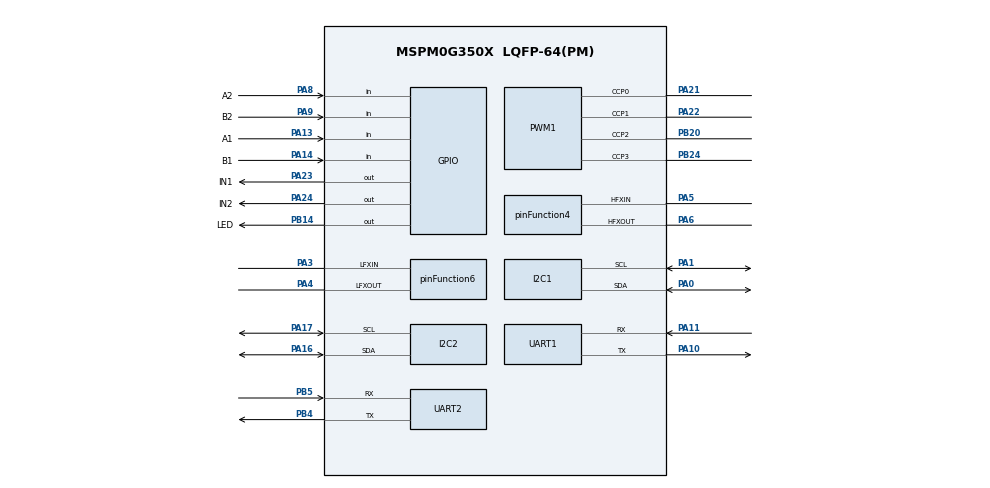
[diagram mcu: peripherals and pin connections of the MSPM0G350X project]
/**
 * @cliArgs --device "MSPM0G350X" --part "Default" --package "LQFP-64(PM)" --product "mspm0_sdk@2.05.01.01"
 * @versions {"tool":"1.24.0+4110"}
 */

/**
 * Import the modules used in this configuration.
 */
const GPIO   = scripting.addModule("/ti/driverlib/GPIO", {}, false);
const GPIO1  = GPIO.addInstance();
const GPIO2  = GPIO.addInstance();
const GPIO3  = GPIO.addInstance();
const I2C    = scripting.addModule("/ti/driverlib/I2C", {}, false);
const I2C1   = I2C.addInstance();
const I2C2   = I2C.addInstance();
const PWM    = scripting.addModule("/ti/driverlib/PWM", {}, false);
const PWM1   = PWM.addInstance();
const SYSCTL = scripting.addModule("/ti/driverlib/SYSCTL");
const TIMER  = scripting.addModule("/ti/driverlib/TIMER", {}, false);
const TIMER1 = TIMER.addInstance();
const UART   = scripting.addModule("/ti/driverlib/UART", {}, false);
const UART1  = UART.addInstance();
const UART2  = UART.addInstance();

/**
 * Write custom configuration values to the imported modules.
 */
const divider2       = system.clockTree["HFCLK4MFPCLKDIV"];
divider2.divideValue = 10;

const divider4       = system.clockTree["PLL_CLK0_DIV"];
divider4.divideValue = 4;

const divider9       = system.clockTree["UDIV"];
divider9.divideValue = 2;

const gate7  = system.clockTree["MFCLKGATE"];
gate7.enable = true;

const gate8  = system.clockTree["MFPCLKGATE"];
gate8.enable = true;

const multiplier2         = system.clockTree["PLL_QDIV"];
multiplier2.multiplyValue = 10;

const mux2       = system.clockTree["CANCLKMUX"];
mux2.inputSelect = "CANCLKMUX_PLLCLK1_OUT";

const mux4       = system.clockTree["EXHFMUX"];
mux4.inputSelect = "EXHFMUX_XTAL";

const mux5       = system.clockTree["EXLFMUX"];
mux5.inputSelect = "EXLFMUX_XTAL";

const mux8       = system.clockTree["HSCLKMUX"];
mux8.inputSelect = "HSCLKMUX_SYSPLL0";

const pinFunction4                        = system.clockTree["HFXT"];
pinFunction4.inputFreq                    = 40;
pinFunction4.enable                       = true;
pinFunction4.peripheral.$assign           = "SYSCTL";
pinFunction4.peripheral.hfxInPin.$assign  = "PA5";
pinFunction4.peripheral.hfxOutPin.$assign = "PA6";

const pinFunction6                        = system.clockTree["LFXT"];
pinFunction6.inputFreq                    = 32.768;
pinFunction6.enable                       = true;
pinFunction6.peripheral.$assign           = "SYSCTL";
pinFunction6.peripheral.lfxInPin.$assign  = "PA3";
pinFunction6.peripheral.lfxOutPin.$assign = "PA4";

GPIO1.$name                         = "DEBUG";
GPIO1.associatedPins[0].$name       = "LED";
GPIO1.associatedPins[0].assignedPin = "14";
GPIO1.associatedPins[0].pin.$assign = "PB14";

const Board = scripting.addModule("/ti/driverlib/Board", {}, false);

GPIO2.$name                         = "ENCODER";
GPIO2.associatedPins.create(4);
GPIO2.associatedPins[0].direction   = "INPUT";
GPIO2.associatedPins[0].interruptEn = true;
GPIO2.associatedPins[0].polarity    = "RISE";
GPIO2.associatedPins[0].$name       = "A1";
GPIO2.associatedPins[0].pin.$assign = "PA13";
GPIO2.associatedPins[1].direction   = "INPUT";
GPIO2.associatedPins[1].interruptEn = true;
GPIO2.associatedPins[1].polarity    = "RISE";
GPIO2.associatedPins[1].$name       = "B1";
GPIO2.associatedPins[1].pin.$assign = "PA14";
GPIO2.associatedPins[2].$name       = "A2";
GPIO2.associatedPins[2].direction   = "INPUT";
GPIO2.associatedPins[2].interruptEn = true;
GPIO2.associatedPins[2].polarity    = "RISE";
GPIO2.associatedPins[2].pin.$assign = "PA8";
GPIO2.associatedPins[3].$name       = "B2";
GPIO2.associatedPins[3].direction   = "INPUT";
GPIO2.associatedPins[3].interruptEn = true;
GPIO2.associatedPins[3].polarity    = "RISE";
GPIO2.associatedPins[3].pin.$assign = "PA9";

GPIO3.$name                         = "MOTOR_DIR";
GPIO3.port                          = "PORTA";
GPIO3.associatedPins.create(2);
GPIO3.associatedPins[0].$name       = "IN1";
GPIO3.associatedPins[0].pin.$assign = "PA23";
GPIO3.associatedPins[1].$name       = "IN2";
GPIO3.associatedPins[1].pin.$assign = "PA24";

I2C1.$name                           = "I2C_0";
I2C1.basicEnableController           = true;
I2C1.basicControllerStandardBusSpeed = "Fast";
I2C1.peripheral.$assign              = "I2C0";
I2C1.peripheral.sdaPin.$assign       = "PA0";
I2C1.peripheral.sclPin.$assign       = "PA1";
I2C1.sdaPinConfig.$name              = "ti_driverlib_gpio_GPIOPinGeneric0";
I2C1.sclPinConfig.$name              = "ti_driverlib_gpio_GPIOPinGeneric1";

I2C2.$name                           = "I2C_1";
I2C2.basicEnableController           = true;
I2C2.basicControllerStandardBusSpeed = "Fast";
I2C2.peripheral.$assign              = "I2C1";
I2C2.peripheral.sdaPin.$assign       = "PA16";
I2C2.peripheral.sclPin.$assign       = "PA17";
I2C2.sdaPinConfig.$name              = "ti_driverlib_gpio_GPIOPinGeneric4";
I2C2.sclPinConfig.$name              = "ti_driverlib_gpio_GPIOPinGeneric5";

PWM1.clockDivider                       = 8;
PWM1.ccIndex                            = [0,1,2,3];
PWM1.pwmMode                            = "EDGE_ALIGN_UP";
PWM1.$name                              = "MOTOR_PWM";
PWM1.PWM_CHANNEL_0.$name                = "ti_driverlib_pwm_PWMTimerCC0";
PWM1.PWM_CHANNEL_1.$name                = "ti_driverlib_pwm_PWMTimerCC1";
PWM1.ccp0PinConfig.direction            = scripting.forceWrite("OUTPUT");
PWM1.ccp0PinConfig.hideOutputInversion  = scripting.forceWrite(false);
PWM1.ccp0PinConfig.onlyInternalResistor = scripting.forceWrite(false);
PWM1.ccp0PinConfig.passedPeripheralType = scripting.forceWrite("Digital");
PWM1.ccp0PinConfig.$name                = "ti_driverlib_gpio_GPIOPinGeneric6";
PWM1.ccp1PinConfig.direction            = scripting.forceWrite("OUTPUT");
PWM1.ccp1PinConfig.hideOutputInversion  = scripting.forceWrite(false);
PWM1.ccp1PinConfig.onlyInternalResistor = scripting.forceWrite(false);
PWM1.ccp1PinConfig.passedPeripheralType = scripting.forceWrite("Digital");
PWM1.ccp1PinConfig.$name                = "ti_driverlib_gpio_GPIOPinGeneric7";
PWM1.peripheral.$assign                 = "TIMA0";
PWM1.peripheral.ccp0Pin.$assign         = "PA21";
PWM1.peripheral.ccp1Pin.$assign         = "PA22";
PWM1.peripheral.ccp2Pin.$assign         = "PB20";
PWM1.peripheral.ccp3Pin.$assign         = "PB24";
PWM1.PWM_CHANNEL_2.$name                = "ti_driverlib_pwm_PWMTimerCC2";
PWM1.PWM_CHANNEL_3.$name                = "ti_driverlib_pwm_PWMTimerCC3";
PWM1.ccp2PinConfig.direction            = scripting.forceWrite("OUTPUT");
PWM1.ccp2PinConfig.hideOutputInversion  = scripting.forceWrite(false);
PWM1.ccp2PinConfig.onlyInternalResistor = scripting.forceWrite(false);
PWM1.ccp2PinConfig.passedPeripheralType = scripting.forceWrite("Digital");
PWM1.ccp2PinConfig.$name                = "ti_driverlib_gpio_GPIOPinGeneric8";
PWM1.ccp3PinConfig.direction            = scripting.forceWrite("OUTPUT");
PWM1.ccp3PinConfig.hideOutputInversion  = scripting.forceWrite(false);
PWM1.ccp3PinConfig.onlyInternalResistor = scripting.forceWrite(false);
PWM1.ccp3PinConfig.passedPeripheralType = scripting.forceWrite("Digital");
PWM1.ccp3PinConfig.$name                = "ti_driverlib_gpio_GPIOPinGeneric9";

SYSCTL.forceDefaultClkConfig = true;
SYSCTL.clockTreeEn           = true;
scripting.suppress("For best practices when the CPUCLK is running at 32MHz and above, clear the flash status bit using DL_FlashCTL_executeClearStatus\\(\\) before executing any flash operation\\. Otherwise there may be false positives\\.", SYSCTL);

TIMER1.timerClkDiv        = 8;
TIMER1.$name              = "TIMER_ENC";
TIMER1.timerClkPrescale   = 10;
TIMER1.timerMode          = "PERIODIC";
TIMER1.timerPeriod        = "0.02";
TIMER1.interrupts         = ["ZERO"];
TIMER1.interruptPriority  = "2";
TIMER1.peripheral.$assign = "TIMG0";

UART1.targetBaudRate                   = 115200;
UART1.uartClkSrc                       = "MFCLK";
UART1.$name                            = "UART_DEBUG";
UART1.peripheral.$assign               = "UART0";
UART1.peripheral.rxPin.$assign         = "PA11";
UART1.peripheral.txPin.$assign         = "PA10";
UART1.txPinConfig.direction            = scripting.forceWrite("OUTPUT");
UART1.txPinConfig.hideOutputInversion  = scripting.forceWrite(false);
UART1.txPinConfig.onlyInternalResistor = scripting.forceWrite(false);
UART1.txPinConfig.passedPeripheralType = scripting.forceWrite("Digital");
UART1.txPinConfig.$name                = "ti_driverlib_gpio_GPIOPinGeneric2";
UART1.rxPinConfig.hideOutputInversion  = scripting.forceWrite(false);
UART1.rxPinConfig.onlyInternalResistor = scripting.forceWrite(false);
UART1.rxPinConfig.passedPeripheralType = scripting.forceWrite("Digital");
UART1.rxPinConfig.$name                = "ti_driverlib_gpio_GPIOPinGeneric3";

UART2.$name                            = "UART_JY901S";
UART2.enabledInterrupts                = ["RX"];
UART2.targetBaudRate                   = 115200;
UART2.uartClkSrc                       = "MFCLK";
UART2.peripheral.$assign               = "UART1";
UART2.peripheral.rxPin.$assign         = "PB5";
UART2.peripheral.txPin.$assign         = "PB4";
UART2.txPinConfig.direction            = scripting.forceWrite("OUTPUT");
UART2.txPinConfig.hideOutputInversion  = scripting.forceWrite(false);
UART2.txPinConfig.onlyInternalResistor = scripting.forceWrite(false);
UART2.txPinConfig.passedPeripheralType = scripting.forceWrite("Digital");
UART2.txPinConfig.$name                = "ti_driverlib_gpio_GPIOPinGeneric10";
UART2.rxPinConfig.hideOutputInversion  = scripting.forceWrite(false);
UART2.rxPinConfig.onlyInternalResistor = scripting.forceWrite(false);
UART2.rxPinConfig.passedPeripheralType = scripting.forceWrite("Digital");
UART2.rxPinConfig.$name                = "ti_driverlib_gpio_GPIOPinGeneric11";

/**
 * Pinmux solution for unlocked pins/peripherals. This ensures that minor changes to the automatic solver in a future
 * version of the tool will not impact the pinmux you originally saw.  These lines can be completely deleted in order to
 * re-solve from scratch.
 */
Board.peripheral.$suggestSolution          = "DEBUGSS";
Board.peripheral.swclkPin.$suggestSolution = "PA20";
Board.peripheral.swdioPin.$suggestSolution = "PA19";
